AUTOSAR XML (schema 00050)
package /MICROSAR/BswM_swc
  5 x mode declaration group, all with category=EXPLICIT_ORDER:
    ESH_Mode: initial-mode=STARTUP, on-transition-value=5
      5 x mode:
        STARTUP: value=0
        RUN: value=1
        POSTRUN: value=2
        WAKEUP: value=3
        SHUTDOWN: value=4
    ESH_RunRequest: initial-mode=RELEASED, on-transition-value=2
      mode RELEASED: value=0
      mode REQUESTED: value=1
    DtcSettingClearFlagModeGrp: initial-mode=FALSE, on-transition-value=2
      mode TRUE: value=1
      mode FALSE: value=0
    BswM_PreviousNMState: initial-mode=NM_STATE_BUS_SLEEP, on-transition-value=6
      6 x mode:
        NM_STATE_BUS_SLEEP: value=1
        NM_STATE_NORMAL: value=4
        NM_STATE_PREPARE_SLEEP: value=2
        NM_STATE_READY_SLEEP: value=3
        NM_STATE_REPEAT: value=5
        NM_UINIT: value=0
    CalDataProSCCalStatus: initial-mode=SC_CAL_NOT_STARTED, on-transition-value=2
      mode SC_CAL_NOT_STARTED: value=0
      mode SC_CAL_FINISHED: value=1
  data type mapping set BswMMappingSet  # Contains Mapping for ModeDeclarations Groups which are provided by BswM.
    mode-request-type-maps:
      implementation-data-type=BswM_ESH_Mode, mode-group=ESH_Mode
      implementation-data-type=BswM_ESH_RunRequest, mode-group=ESH_RunRequest
      implementation-data-type=BswM_DtcSettingClearFlagModeGrp, mode-group=DtcSettingClearFlagModeGrp
      implementation-data-type=BswM_BswM_PreviousNMState, mode-group=BswM_PreviousNMState
      implementation-data-type=BswM_CalDataProSCCalStatus, mode-group=CalDataProSCCalStatus
      implementation-data-type=Dcm_EcuResetType, mode-group=DcmEcuReset
package /MICROSAR/BswM_swc/ComponentTypes
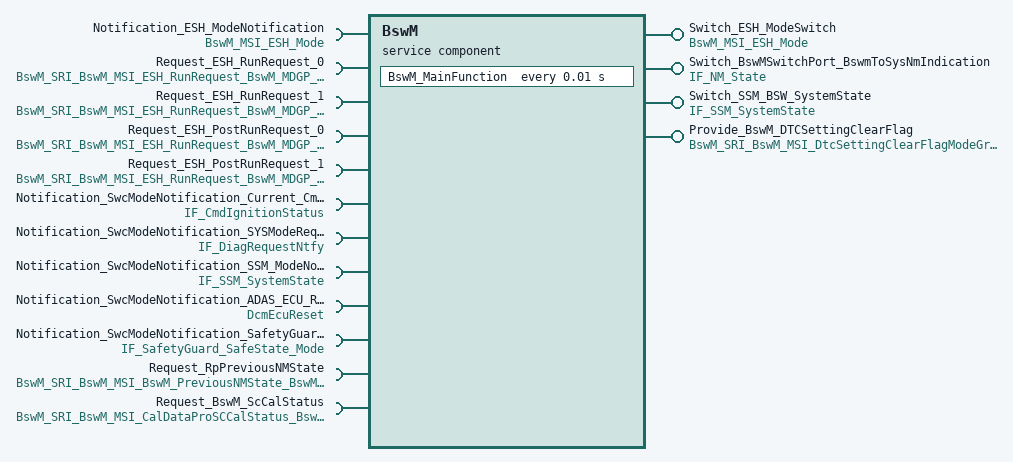
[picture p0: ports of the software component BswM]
  service sw component type BswM: category=SERVICE_COMPONENT
    provide port Switch_ESH_ModeSwitch: provided-interface=BswM_MSI_ESH_Mode
    5 x require port:
      Notification_ESH_ModeNotification: required-interface=BswM_MSI_ESH_Mode
      Request_ESH_RunRequest_0: nonqueued-receiver-com-spec{data-element=BswM_SRI_BswM_MSI_ESH_RunRequest_BswM_MDGP_ESH_RunRequest/requestedMode, handle-out-of-range-status=SILENT, init-value=RELEASED}, required-interface=BswM_SRI_BswM_MSI_ESH_RunRequest_BswM_MDGP_ESH_RunRequest
      Request_ESH_RunRequest_1: nonqueued-receiver-com-spec{data-element=BswM_SRI_BswM_MSI_ESH_RunRequest_BswM_MDGP_ESH_RunRequest/requestedMode, handle-out-of-range-status=SILENT, init-value=RELEASED}, required-interface=BswM_SRI_BswM_MSI_ESH_RunRequest_BswM_MDGP_ESH_RunRequest
      Request_ESH_PostRunRequest_0: nonqueued-receiver-com-spec{data-element=BswM_SRI_BswM_MSI_ESH_RunRequest_BswM_MDGP_ESH_RunRequest/requestedMode, handle-out-of-range-status=SILENT, init-value=RELEASED}, required-interface=BswM_SRI_BswM_MSI_ESH_RunRequest_BswM_MDGP_ESH_RunRequest
      Request_ESH_PostRunRequest_1: nonqueued-receiver-com-spec{data-element=BswM_SRI_BswM_MSI_ESH_RunRequest_BswM_MDGP_ESH_RunRequest/requestedMode, handle-out-of-range-status=SILENT, init-value=RELEASED}, required-interface=BswM_SRI_BswM_MSI_ESH_RunRequest_BswM_MDGP_ESH_RunRequest
    provide port Switch_BswMSwitchPort_BswmToSysNmIndication: provided-interface=IF_NM_State
    require port Notification_SwcModeNotification_Current_CmdIgnition: required-interface=IF_CmdIgnitionStatus
    require port Notification_SwcModeNotification_SYSModeRequestType: required-interface=IF_DiagRequestNtfy
    provide port Switch_SSM_BSW_SystemState: provided-interface=IF_SSM_SystemState
    require port Notification_SwcModeNotification_SSM_ModeNotification_State: required-interface=IF_SSM_SystemState
    require port Notification_SwcModeNotification_ADAS_ECU_Reset: required-interface=DcmEcuReset
    require port Notification_SwcModeNotification_SafetyGuard_SysResetReq: required-interface=IF_SafetyGuard_SafeState_Mode
    provide port Provide_BswM_DTCSettingClearFlag: nonqueued-sender-com-spec=BswM_SRI_BswM_MSI_DtcSettingClearFlagModeGrp_BswM_MDGP_DtcSettingClearFlagModeGrp/requestedMode, provided-interface=BswM_SRI_BswM_MSI_DtcSettingClearFlagModeGrp_BswM_MDGP_DtcSettingClearFlagModeGrp
    require port Request_RpPreviousNMState: nonqueued-receiver-com-spec{data-element=BswM_SRI_BswM_MSI_BswM_PreviousNMState_BswM_MDGP_BswM_PreviousNMState/requestedMode, handle-out-of-range-status=SILENT, init-value=NM_STATE_BUS_SLEEP}, required-interface=BswM_SRI_BswM_MSI_BswM_PreviousNMState_BswM_MDGP_BswM_PreviousNMState
    require port Request_BswM_ScCalStatus: nonqueued-receiver-com-spec{data-element=BswM_SRI_BswM_MSI_CalDataProSCCalStatus_BswM_MDGP_CalDataProSCCalStatus/requestedMode, handle-out-of-range-status=SILENT, init-value=SC_CAL_NOT_STARTED}, required-interface=BswM_SRI_BswM_MSI_CalDataProSCCalStatus_BswM_MDGP_CalDataProSCCalStatus
    behavior BswMInternalBehavior: data-type-mapping=BswMMappingSet, handle-termination-and-restart=NO-SUPPORT, included-data-type-set=data-type=[BswM_ESH_Mode, BswM_ESH_RunRequest, BswM_DtcSettingClearFlagModeGrp, BswM_BswM_PreviousNMState, BswM_CalDataProSCCalStatus]
      timing event Timer_BswM_MainFunction: start-on-event=BswM_MainFunction, period=0.01
      port-api-options:
        enable-take-address=true, indirect-api=false, port=Switch_ESH_ModeSwitch
        enable-take-address=true, indirect-api=false, port=Switch_BswMSwitchPort_BswmToSysNmIndication
        enable-take-address=true, indirect-api=false, port=Switch_SSM_BSW_SystemState
        enable-take-address=true, indirect-api=false, port=Notification_ESH_ModeNotification
        enable-take-address=true, indirect-api=false, port=Notification_SwcModeNotification_Current_CmdIgnition
        enable-take-address=true, indirect-api=false, port=Notification_SwcModeNotification_SYSModeRequestType
        enable-take-address=true, indirect-api=false, port=Notification_SwcModeNotification_SSM_ModeNotification_State
        enable-take-address=true, indirect-api=false, port=Notification_SwcModeNotification_ADAS_ECU_Reset
        enable-take-address=true, indirect-api=false, port=Notification_SwcModeNotification_SafetyGuard_SysResetReq
        enable-take-address=true, indirect-api=false, port=Request_ESH_RunRequest_0
        enable-take-address=true, indirect-api=false, port=Request_ESH_RunRequest_1
        enable-take-address=true, indirect-api=false, port=Request_ESH_PostRunRequest_0
        enable-take-address=true, indirect-api=false, port=Request_ESH_PostRunRequest_1
        enable-take-address=true, indirect-api=false, port=Request_RpPreviousNMState
        enable-take-address=true, indirect-api=false, port=Provide_BswM_DTCSettingClearFlag
        enable-take-address=true, indirect-api=false, port=Request_BswM_ScCalStatus
      runnable BswM_MainFunction
        data-receive-point-by-arguments:
          6 x access:
            DataReceivePointBswM_MainFunction_Request_ESH_RunRequest_0_requestedMode: accessed-variable=Request_ESH_RunRequest_0.requestedMode
            DataReceivePointBswM_MainFunction_Request_ESH_RunRequest_1_requestedMode: accessed-variable=Request_ESH_RunRequest_1.requestedMode
            DataReceivePointBswM_MainFunction_Request_ESH_PostRunRequest_0_requestedMode: accessed-variable=Request_ESH_PostRunRequest_0.requestedMode
            DataReceivePointBswM_MainFunction_Request_ESH_PostRunRequest_1_requestedMode: accessed-variable=Request_ESH_PostRunRequest_1.requestedMode
            DataReceivePointBswM_MainFunction_Request_RpPreviousNMState_requestedMode: accessed-variable=Request_RpPreviousNMState.requestedMode
            DataReceivePointBswM_MainFunction_Request_BswM_ScCalStatus_requestedMode: accessed-variable=Request_BswM_ScCalStatus.requestedMode
        data-send-points:
          access DataSendPointBswM_MainFunction_Provide_BswM_DTCSettingClearFlag_requestedMode: accessed-variable=Provide_BswM_DTCSettingClearFlag.requestedMode
        mode-access-points:
          Notification_ESH_ModeNotification.BswM_MDGP_ESH_Mode
          Notification_SwcModeNotification_Current_CmdIgnition.Current_CmdIgnition
          Notification_SwcModeNotification_SYSModeRequestType.SYSModeRequestType
          Notification_SwcModeNotification_SSM_ModeNotification_State.Mode
          Notification_SwcModeNotification_ADAS_ECU_Reset.DcmEcuReset
          Notification_SwcModeNotification_SafetyGuard_SysResetReq.Mode
        mode switch point ModeSwitchPointBswM_MainFunction_Switch_ESH_ModeSwitch_BswM_MDGP_ESH_Mode: mode-group=Switch_ESH_ModeSwitch.BswM_MDGP_ESH_Mode
        mode switch point ModeSwitchPointBswM_MainFunction_Switch_BswMSwitchPort_BswmToSysNmIndication_Mode: mode-group=Switch_BswMSwitchPort_BswmToSysNmIndication.Mode
        mode switch point ModeSwitchPointBswM_MainFunction_Switch_SSM_BSW_SystemState_Mode: mode-group=Switch_SSM_BSW_SystemState.Mode
  swc implementation BswMImplementation: programming-language=C, behavior=BswMInternalBehavior
    resource consumption BswMResourceConsumption
      5 x memory section:
        BswM_START_SEC_CODE: sw-addrmethod=CODE, symbol=CODE
        BswM_START_SEC_CONST_UNSPECIFIED: alignment=UNSPECIFIED, sw-addrmethod=CONST, symbol=CONST_UNSPECIFIED
        BswM_START_SEC_VAR_NOINIT_UNSPECIFIED: alignment=UNSPECIFIED, sw-addrmethod=VAR_NO_INIT, symbol=VAR_NOINIT_UNSPECIFIED
        BswM_START_SEC_VAR_INIT_UNSPECIFIED: alignment=UNSPECIFIED, sw-addrmethod=VAR_INIT, symbol=VAR_INIT_UNSPECIFIED
        BswM_START_SEC_VAR_ZERO_INIT_UNSPECIFIED: alignment=UNSPECIFIED, sw-addrmethod=VAR_CLEARED, symbol=VAR_ZERO_INIT_UNSPECIFIED
package /MICROSAR/BswM_swc/DataTypes
  5 x impl type, all with category=TYPE_REFERENCE, range raw 0..255, implementation-data-type=uint8:
    BswM_ESH_Mode: compu {0=STARTUP, 1=RUN, 2=POSTRUN, 3=WAKEUP, 4=SHUTDOWN}  # Unique value for each user
    BswM_ESH_RunRequest: compu {0=RELEASED, 1=REQUESTED}  # Unique value for each user
    BswM_DtcSettingClearFlagModeGrp: compu {1=TRUE, 0=FALSE}  # Unique value for each user
    BswM_BswM_PreviousNMState: compu {1=NM_STATE_BUS_SLEEP, 4=NM_STATE_NORMAL, 2=NM_STATE_PREPARE_SLEEP, 3=NM_STATE_READY_SLEEP, 5=NM_STATE_REPEAT, 0=NM_UINIT}  # Unique value for each user
    BswM_CalDataProSCCalStatus: compu {0=SC_CAL_NOT_STARTED, 1=SC_CAL_FINISHED}  # Unique value for each user
package /MICROSAR/BswM_swc/Interfaces
  mode switch interface BswM_MSI_ESH_Mode: is-service=true, service-kind=BASIC-SOFTWARE-MODE-MANAGER
    mode group BswM_MDGP_ESH_Mode: type=ESH_Mode
  sender receiver interface BswM_SRI_BswM_MSI_ESH_Mode_BswM_MDGP_ESH_Mode: is-service=true, service-kind=BASIC-SOFTWARE-MODE-MANAGER
    data requestedMode: type=BswM_ESH_Mode
  mode switch interface BswM_MSI_ESH_RunRequest: is-service=true, service-kind=BASIC-SOFTWARE-MODE-MANAGER
    mode group BswM_MDGP_ESH_RunRequest: type=ESH_RunRequest
  sender receiver interface BswM_SRI_BswM_MSI_ESH_RunRequest_BswM_MDGP_ESH_RunRequest: is-service=true, service-kind=BASIC-SOFTWARE-MODE-MANAGER
    data requestedMode: type=BswM_ESH_RunRequest
  mode switch interface BswM_MSI_DtcSettingClearFlagModeGrp: is-service=true, service-kind=BASIC-SOFTWARE-MODE-MANAGER
    mode group BswM_MDGP_DtcSettingClearFlagModeGrp: type=DtcSettingClearFlagModeGrp
  sender receiver interface BswM_SRI_BswM_MSI_DtcSettingClearFlagModeGrp_BswM_MDGP_DtcSettingClearFlagModeGrp: is-service=true, service-kind=BASIC-SOFTWARE-MODE-MANAGER
    data requestedMode: type=BswM_DtcSettingClearFlagModeGrp
  mode switch interface BswM_MSI_BswM_PreviousNMState: is-service=true, service-kind=BASIC-SOFTWARE-MODE-MANAGER
    mode group BswM_MDGP_BswM_PreviousNMState: type=BswM_PreviousNMState
  sender receiver interface BswM_SRI_BswM_MSI_BswM_PreviousNMState_BswM_MDGP_BswM_PreviousNMState: is-service=true, service-kind=BASIC-SOFTWARE-MODE-MANAGER
    data requestedMode: type=BswM_BswM_PreviousNMState
  mode switch interface BswM_MSI_CalDataProSCCalStatus: is-service=true, service-kind=BASIC-SOFTWARE-MODE-MANAGER
    mode group BswM_MDGP_CalDataProSCCalStatus: type=CalDataProSCCalStatus
  sender receiver interface BswM_SRI_BswM_MSI_CalDataProSCCalStatus_BswM_MDGP_CalDataProSCCalStatus: is-service=true, service-kind=BASIC-SOFTWARE-MODE-MANAGER
    data requestedMode: type=BswM_CalDataProSCCalStatus
